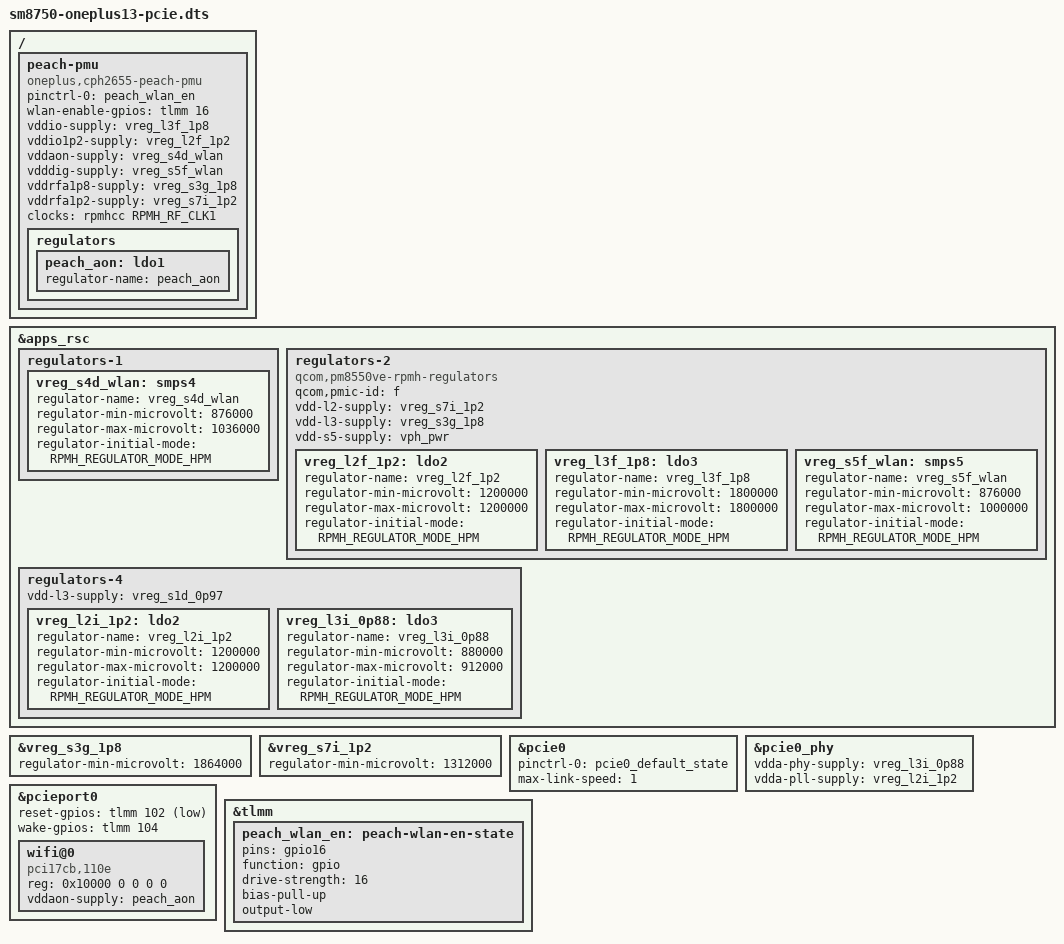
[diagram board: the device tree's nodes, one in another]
// SPDX-License-Identifier: BSD-3-Clause
/* CPH2655 Peach PCIe enumeration only. No WLAN firmware or radio driver.
 * Rails and GPIOs: captured stock sun-peach-cnss-v8 device tree.
 * Power-sequencing layout cross-checked against renhiyama's pagani port,
 * commit 2635bc17978b5e0eaff7ad67cb85f3fa22d37d64 (BSD-3-Clause).
 * This profile requires the optional Peach power-sequencing patch/modules.
 */
#include "sm8750-oneplus13-sensors.dts"

&apps_rsc {
	regulators-1 {
		vreg_s4d_wlan: smps4 {
			regulator-name = "vreg_s4d_wlan";
			regulator-min-microvolt = <876000>;
			regulator-max-microvolt = <1036000>;
			regulator-initial-mode = <RPMH_REGULATOR_MODE_HPM>;
		};
	};
	regulators-2 {
		compatible = "qcom,pm8550ve-rpmh-regulators";
		qcom,pmic-id = "f";
		vdd-l2-supply = <&vreg_s7i_1p2>;
		vdd-l3-supply = <&vreg_s3g_1p8>;
		vdd-s5-supply = <&vph_pwr>;
		vreg_l2f_1p2: ldo2 {
			regulator-name = "vreg_l2f_1p2";
			regulator-min-microvolt = <1200000>;
			regulator-max-microvolt = <1200000>;
			regulator-initial-mode = <RPMH_REGULATOR_MODE_HPM>;
		};
		vreg_l3f_1p8: ldo3 {
			regulator-name = "vreg_l3f_1p8";
			regulator-min-microvolt = <1800000>;
			regulator-max-microvolt = <1800000>;
			regulator-initial-mode = <RPMH_REGULATOR_MODE_HPM>;
		};
		vreg_s5f_wlan: smps5 {
			regulator-name = "vreg_s5f_wlan";
			regulator-min-microvolt = <876000>;
			regulator-max-microvolt = <1000000>;
			regulator-initial-mode = <RPMH_REGULATOR_MODE_HPM>;
		};
	};
	regulators-4 {
		vdd-l3-supply = <&vreg_s1d_0p97>;
		vreg_l2i_1p2: ldo2 {
			regulator-name = "vreg_l2i_1p2";
			regulator-min-microvolt = <1200000>;
			regulator-max-microvolt = <1200000>;
			regulator-initial-mode = <RPMH_REGULATOR_MODE_HPM>;
		};
		vreg_l3i_0p88: ldo3 {
			regulator-name = "vreg_l3i_0p88";
			regulator-min-microvolt = <880000>;
			regulator-max-microvolt = <912000>;
			regulator-initial-mode = <RPMH_REGULATOR_MODE_HPM>;
		};
	};
};

/* Shared parent rails: stay within their stock limits while satisfying WLAN.
 * The existing downstream LDOs retain their original output voltages. */
&vreg_s3g_1p8 { regulator-min-microvolt = <1864000>; };
&vreg_s7i_1p2 { regulator-min-microvolt = <1312000>; };

&pcie0 {
	pinctrl-names = "default";
	pinctrl-0 = <&pcie0_default_state>;
	/* Conservative link speed for enumeration, not a throughput test. */
	max-link-speed = <1>;
	status = "okay";
};

&pcie0_phy {
	vdda-phy-supply = <&vreg_l3i_0p88>;
	vdda-pll-supply = <&vreg_l2i_1p2>;
	status = "okay";
};

&pcieport0 {
	reset-gpios = <&tlmm 102 GPIO_ACTIVE_LOW>;
	wake-gpios = <&tlmm 104 GPIO_ACTIVE_HIGH>;
	wifi@0 {
		compatible = "pci17cb,110e";
		reg = <0x10000 0 0 0 0>;
		vddaon-supply = <&peach_aon>;
	};
};

/ {
	peach-pmu {
		/* Private bring-up binding, no assumption about a marketed chip name. */
		compatible = "oneplus,cph2655-peach-pmu";
		pinctrl-names = "default";
		pinctrl-0 = <&peach_wlan_en>;
		wlan-enable-gpios = <&tlmm 16 GPIO_ACTIVE_HIGH>;
		vddio-supply = <&vreg_l3f_1p8>;
		vddio1p2-supply = <&vreg_l2f_1p2>;
		vddaon-supply = <&vreg_s4d_wlan>;
		vdddig-supply = <&vreg_s5f_wlan>;
		vddrfa1p8-supply = <&vreg_s3g_1p8>;
		vddrfa1p2-supply = <&vreg_s7i_1p2>;
		clocks = <&rpmhcc RPMH_RF_CLK1>;
		regulators {
			/* Topology marker for upstream pwrseq's consumer matching. */
			peach_aon: ldo1 { regulator-name = "peach_aon"; };
		};
	};
};

&tlmm {
	peach_wlan_en: peach-wlan-en-state {
		pins = "gpio16";
		function = "gpio";
		drive-strength = <16>;
		bias-pull-up;
		/* Power sequencer raises WLAN_EN only after voting all six rails. */
		output-low;
	};
};
